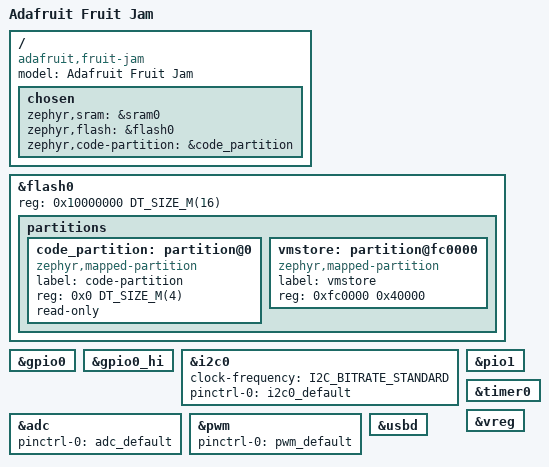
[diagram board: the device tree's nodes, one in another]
/* RP2350B composition follows Zephyr's Metro RP2350 board, Pete Johanson 2025.
 * Fruit Jam wiring: official Adafruit schematic 252dc094.
 * SPDX-License-Identifier: Apache-2.0
 */
/dts-v1/;
#include <raspberrypi/rpi_pico/rp2350b.dtsi>
#include <raspberrypi/rpi_pico/m33.dtsi>
#include <zephyr/dt-bindings/gpio/gpio.h>
#include <zephyr/dt-bindings/i2c/i2c.h>
#include "adafruit_fruit_jam-pinctrl.dtsi"
/ {
	model = "Adafruit Fruit Jam";
	compatible = "adafruit,fruit-jam";
	chosen {
		zephyr,sram = &sram0;
		zephyr,flash = &flash0;
		zephyr,code-partition = &code_partition;
	};
	/* No console/UART alias: native USB belongs exclusively to SmallVM.
	 * GPIO8/9 remain untouched (ESP32-C6 UART), as do all output peripherals. */
};
&flash0 {
	reg = <0x10000000 DT_SIZE_M(16)>;
	ranges = <0x0 0x10000000 DT_SIZE_M(16)>;
	partitions {
		ranges;
		#address-cells = <1>;
		#size-cells = <1>;
		/* The SoC linker embeds IMAGE_DEF in the initial app region. Starting
		 * at native flash base also gives ELF/UF2 readers a contiguous image. */
		code_partition: partition@0 {
			compatible = "zephyr,mapped-partition";
			label = "code-partition";
			reg = <0x0 DT_SIZE_M(4)>;
			read-only;
		};
		/* Final 256 KiB: two snapshots, absent from the firmware ELF. */
		vmstore: partition@fc0000 {
			compatible = "zephyr,mapped-partition";
			label = "vmstore";
			reg = <0xfc0000 0x40000>;
		};
	};
};
&gpio0 { status = "okay"; };
&gpio0_hi { status = "okay"; };
&i2c0 {
	clock-frequency = <I2C_BITRATE_STANDARD>;
	pinctrl-0 = <&i2c0_default>;
	pinctrl-names = "default";
	status = "okay";
};
&adc {
	pinctrl-0 = <&adc_default>;
	pinctrl-names = "default";
	status = "okay";
};
&pwm {
	pinctrl-0 = <&pwm_default>;
	pinctrl-names = "default";
	status = "okay";
};
/* PIO1 is reserved for GPIO32 NeoPixels, with its base selected as 16 at first
 * use. Future low-pin USB host belongs on another PIO instance. */
&pio1 { status = "okay"; };
&timer0 { status = "okay"; };
&vreg { status = "okay"; };
zephyr_udc0: &usbd { status = "okay"; };
arduino_i2c: &i2c0 {};
